# ATxmega128A1 register map
Vendor: Atmel; File version: 1.0
CPU: other r0p0, little endian, no MPU, no FPU, 4 interrupt priority bits
Registers are 8-bit, read-write, reset 0x0 unless marked. A register's access mark holds for its fields unless they carry their own. Offsets are from the block's base; lines under a group give offsets from that group; [hi:lo] are bit positions; {n}, {i} and the like mark numbered series; 'fields as' and 'values as' point back to an identical list; <NAME> marks a mode.

## Memory map
0x00000000 FUSE — Non Volatile Memory Controller
0x00000000 GPIO — General Purpose IO
0x00000000 LOCKBIT — Non Volatile Memory Controller
0x00000000 PROD_SIGNATURES — Non Volatile Memory Controller
0x00000010 VPORT0 — Port Configuration
0x00000014 VPORT1 — Port Configuration
0x00000018 VPORT2 — Port Configuration
0x0000001C VPORT3 — Port Configuration
0x0000002E OCD — On-Chip Debug System
0x00000030 CPU
0x00000040 CLK — Clock System
0x00000048 SLEEP — Sleep Controller
0x00000050 OSC — Oscillator
0x00000060 DFLLRC32M — DFLL
0x00000068 DFLLRC2M — DFLL
0x00000070 PR — Clock System
0x00000078 RST — Reset
0x00000080 WDT — Watch-Dog Timer
0x00000090 MCU — MCU Control
0x000000A0 PMIC — Programmable Multi-level Interrupt Controller
0x000000B0 PORT_CFG — Port Configuration
0x000000C0 AES — AES Module
0x00000100 DMA — DMA Controller
0x00000180 EVSYS — Event System
0x000001C0 NVM — Non Volatile Memory Controller
0x00000200 ADCA — Analog/Digital Converter
0x00000240 ADCB — Analog/Digital Converter
0x00000300 DACA — Digital/Analog Converter
0x00000320 DACB — Digital/Analog Converter
0x00000380 ACA — Analog Comparator
0x00000390 ACB — Analog Comparator
0x00000400 RTC — Real-Time Counter
0x00000440 EBI — External Bus Interface
0x00000480 TWIC — Two-Wire Interface
0x00000490 TWID — Two-Wire Interface
0x000004A0 TWIE — Two-Wire Interface
0x000004B0 TWIF — Two-Wire Interface
0x00000600 PORTA — Port Configuration
0x00000620 PORTB — Port Configuration
0x00000640 PORTC — Port Configuration
0x00000660 PORTD — Port Configuration
0x00000680 PORTE — Port Configuration
0x000006A0 PORTF — Port Configuration
0x000006E0 PORTH — Port Configuration
0x00000700 PORTJ — Port Configuration
0x00000720 PORTK — Port Configuration
0x000007C0 PORTQ — Port Configuration
0x000007E0 PORTR — Port Configuration
0x00000800 TCC0 — 16-bit Timer/Counter With PWM
0x00000840 TCC1 — 16-bit Timer/Counter With PWM
0x00000880 AWEXC — 16-bit Timer/Counter With PWM
0x00000890 HIRESC — 16-bit Timer/Counter With PWM
0x000008A0 USARTC0 — Universal Asynchronous Receiver-Transmitter
0x000008B0 USARTC1 — Universal Asynchronous Receiver-Transmitter
0x000008C0 SPIC — Serial Peripheral Interface
0x000008F8 IRCOM — IR Communication Module
0x00000900 TCD0 — 16-bit Timer/Counter With PWM
0x00000940 TCD1 — 16-bit Timer/Counter With PWM
0x00000990 HIRESD — 16-bit Timer/Counter With PWM
0x000009A0 USARTD0 — Universal Asynchronous Receiver-Transmitter
0x000009B0 USARTD1 — Universal Asynchronous Receiver-Transmitter
0x000009C0 SPID — Serial Peripheral Interface
0x00000A00 TCE0 — 16-bit Timer/Counter With PWM
0x00000A40 TCE1 — 16-bit Timer/Counter With PWM
0x00000A80 AWEXE — 16-bit Timer/Counter With PWM
0x00000A90 HIRESE — 16-bit Timer/Counter With PWM
0x00000AA0 USARTE0 — Universal Asynchronous Receiver-Transmitter
0x00000AB0 USARTE1 — Universal Asynchronous Receiver-Transmitter
0x00000AC0 SPIE — Serial Peripheral Interface
0x00000B00 TCF0 — 16-bit Timer/Counter With PWM
0x00000B40 TCF1 — 16-bit Timer/Counter With PWM
0x00000B90 HIRESF — 16-bit Timer/Counter With PWM
0x00000BA0 USARTF0 — Universal Asynchronous Receiver-Transmitter
0x00000BB0 USARTF1 — Universal Asynchronous Receiver-Transmitter
0x00000BC0 SPIF — Serial Peripheral Interface

## ACA — Analog Comparator
Base 0x00000380
Same registers: ACB 0x00000390
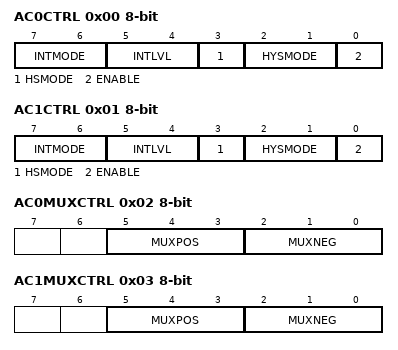
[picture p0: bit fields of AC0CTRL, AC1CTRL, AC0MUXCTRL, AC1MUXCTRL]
0x00 AC0CTRL — Analog Comparator 0 Control
  [7:6] INTMODE — Interrupt Mode
    0=BOTHEDGES (Interrupt on both edges); 2=FALLING (Interrupt on falling edge); 3=RISING (Interrupt on rising edge)
  [5:4] INTLVL — Interrupt Level
    0=OFF (Interrupt disabled); 1=LO (Low level); 2=MED (Medium level); 3=HI (High level)
  [3] HSMODE — High-speed Mode
  [2:1] HYSMODE — Hysteresis Mode
    0=NO (No hysteresis); 1=SMALL (Small hysteresis); 2=LARGE (Large hysteresis)
  [0] ENABLE
0x01 AC1CTRL — Analog Comparator 1 Control
  fields as AC0CTRL
0x02 AC0MUXCTRL — Analog Comparator 0 MUX Control
  [5:3] MUXPOS — MUX Positive Input
    {v}=PIN{v} (v=0..6); 7=DAC (DAC output)
  [2:0] MUXNEG — MUX Negative Input
    0=PIN0; 1=PIN1; 2=PIN3; 3=PIN5; 4=PIN7; 5=DAC (DAC output); 6=BANDGAP (Bandgap Reference); 7=SCALER (Internal voltage scaler)
0x03 AC1MUXCTRL — Analog Comparator 1 MUX Control
  fields as AC0MUXCTRL
0x04 CTRLA — Control Register A
  [0] AC0OUT — Analog Comparator 0 Output Enable
0x05 CTRLB — Control Register B
  [5:0] SCALEFAC — VCC Voltage Scaler Factor
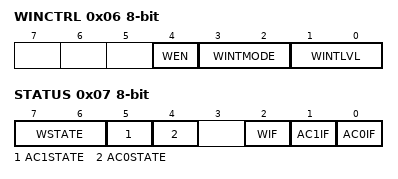
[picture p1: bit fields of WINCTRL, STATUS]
0x06 WINCTRL — Window Mode Control
  [4] WEN — Window Mode Enable
  [3:2] WINTMODE — Window Interrupt Mode
    0=ABOVE (Interrupt on above window); 1=INSIDE (Interrupt on inside window); 2=BELOW (Interrupt on below window); 3=OUTSIDE (Interrupt on outside window)
  [1:0] WINTLVL — Window Interrupt Level
    0=OFF (Interrupt disabled); 1=LO (Low priority); 2=MED (Medium priority); 3=HI (High priority)
0x07 STATUS
  [7:6] WSTATE — Window Mode State
    0=ABOVE (Signal above window); 1=INSIDE (Signal inside window); 2=BELOW (Signal below window)
  [5] AC1STATE — Analog Comparator 1 State
  [4] AC0STATE — Analog Comparator 0 State
  [2] WIF — Window Mode Interrupt Flag
  [1] AC1IF — Analog Comparator 1 Interrupt Flag
  [0] AC0IF — Analog Comparator 0 Interrupt Flag
